# ATSAMD21G18A register map
Vendor: Microchip Technology Inc.; Series: SAMD21; File version: G
CPU: CM0+ r0p1, little endian, no MPU, no FPU, VTOR, 2 interrupt priority bits, 30 interrupts
Registers are 8-bit, read-write, reset 0x0 unless marked. A register's access mark holds for its fields unless they carry their own. Offsets are from the block's base; [hi:lo] are bit positions; {n}, {i} and the like mark numbered series; 'fields as' and 'values as' point back to an identical list.

## EVSYS — Event System Interface
Base 0x42000400; register names take the prefix EVSYS_
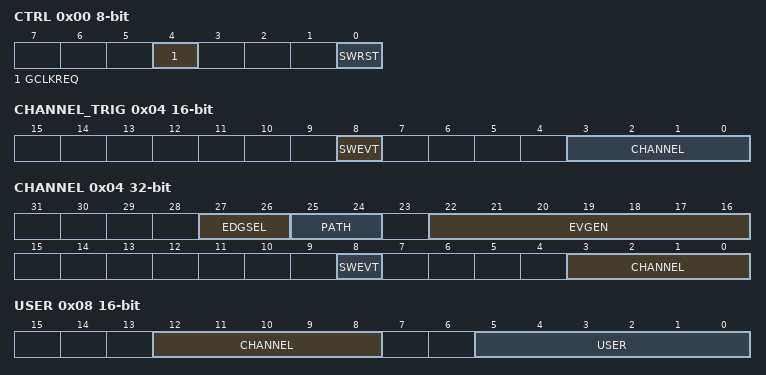
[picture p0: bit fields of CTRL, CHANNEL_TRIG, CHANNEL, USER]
0x00 CTRL wo — Control
  [4] GCLKREQ — Generic Clock Requests
  [0] SWRST — Software Reset
0x04 CHANNEL_TRIG 16-bit — Channel
  [8] SWEVT — Software Event
  [3:0] CHANNEL — Channel Selection
0x04 CHANNEL 32-bit
  [27:26] EDGSEL — Edge Detection Selection
    0=NO_EVT_OUTPUT (No event output when using the resynchronized or synchronous path); 1=RISING_EDGE (Event detection only on the rising edge of the signal from the event generator when using the resynchronized or synchronous path); 2=FALLING_EDGE (Event detection only on the falling edge of the signal from the event generator when using the resynchronized or synchronous path); 3=BOTH_EDGES (Event detection on rising and falling edges of the signal from the event generator when using the resynchronized or synchronous path)
  [25:24] PATH — Path Selection
    0=SYNCHRONOUS (Synchronous path); 1=RESYNCHRONIZED (Resynchronized path); 2=ASYNCHRONOUS (Asynchronous path)
  [22:16] EVGEN — Event Generator Selection
    0=NONE (No event generator selected); 1=RTC_CMP0 (Compare 0 (mode 0 and 1) or Alarm 0 (mode 2)); 2=RTC_CMP1 (Compare 1); 3=RTC_OVF (Overflow); {v}=RTC_PER{v-4} (Period {v-4}) (v=4..11); {v}=EIC_EXTINT{v-12} (External Interrupt {v-12}) (v=12..27); {v}=DMAC_CH{v-30} (Channel {v-30}) (v=30..33); 34=TCC0_OVF (Overflow); 35=TCC0_TRG (Trig); 36=TCC0_CNT (Counter); {v}=TCC0_MCX{v-37} (Match/Capture {v-37}) (v=37..40); 41=TCC1_OVF (Overflow); 42=TCC1_TRG (Trig); 43=TCC1_CNT (Counter); 44=TCC1_MCX0 (Match/Capture 0); 45=TCC1_MCX1 (Match/Capture 1); 46=TCC2_OVF (Overflow); 47=TCC2_TRG (Trig); 48=TCC2_CNT (Counter); 49=TCC2_MCX0 (Match/Capture 0); 50=TCC2_MCX1 (Match/Capture 1); 51=TC0_OVF (Overflow/Underflow); 52=TC0_MC0 (Match/Capture 0); 53=TC0_MC1 (Match/Capture 1); 54=TC1_OVF (Overflow/Underflow); 55=TC1_MC0 (Match/Capture 0); 56=TC1_MC1 (Match/Capture 1); 57=TC2_OVF (Overflow/Underflow); 58=TC2_MC0 (Match/Capture 0); 59=TC2_MC1 (Match/Capture 1); 60=TC3_OVF (Overflow/Underflow); 61=TC3_MC0 (Match/Capture 0); 62=TC3_MC1 (Match/Capture 1); 63=TC4_OVF (Overflow/Underflow); 64=TC4_MC0 (Match/Capture 0); 65=TC4_MC1 (Match/Capture 1); 66=ADC_RESRDY (Result Ready); 67=ADC_WINMON (Window Monitor); 68=AC_COMP0 (Comparator 0); 69=AC_COMP1 (Comparator 1); 70=AC_WIN0 (Window 0); 71=DAC_EMPTY (Data Buffer Empty); 72=PTC_EOC (End of Conversion); 73=PTC_WCOMP (Window Comparator)
  [8] SWEVT — Software Event
  [3:0] CHANNEL — Channel Selection
0x08 USER 16-bit — User Multiplexer
  [12:8] CHANNEL — Channel Event Selection
    0=No Channel Output Selected
  [5:0] USER — User Multiplexer Selection
    {v}=DMAC_CH{v} (Channel {v}) (v=0..3); 4=TCC0_EV0; 5=TCC0_EV1; {v}=TCC0_MC{v-6} (Match/Capture {v-6}) (v=6..9); 10=TCC1_EV0; 11=TCC1_EV1; 12=TCC1_MC0 (Match/Capture 0); 13=TCC1_MC1 (Match/Capture 1); 14=TCC2_EV0; 15=TCC2_EV1; 16=TCC2_MC0 (Match/Capture 0); 17=TCC2_MC1 (Match/Capture 1); {v}=TC{v-18} (v=18..22); 23=ADC_START (ADC start conversion); 24=ADC_SYNC (Flush ADC); 25=AC_COMP0 (Start comparator 0); 26=AC_COMP1 (Start comparator 1); 27=DAC_START (DAC start conversion); 28=PTC_STCONV (PTC start conversion)
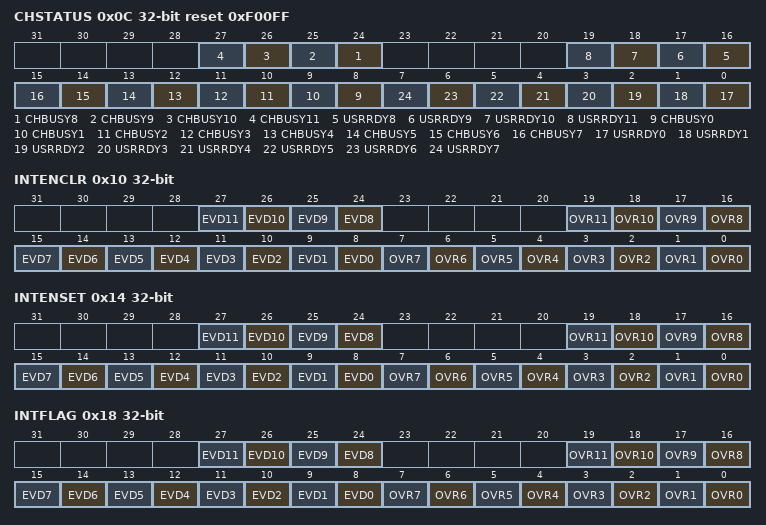
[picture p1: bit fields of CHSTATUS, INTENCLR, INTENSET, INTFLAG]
0x0C CHSTATUS 32-bit ro reset 0xF00FF — Channel Status
  [n+16] CHBUSY{n} (n=8..11) — Channel {n} Busy
  [n+8] USRRDY{n} (n=8..11) — Channel {n} User Ready
  [n+8] CHBUSY{n} (n=0..7) — Channel {n} Busy
  [n] USRRDY{n} (n=0..7) — Channel {n} User Ready
0x10 INTENCLR 32-bit — Interrupt Enable Clear
  [n+16] EVD{n} (n=8..11) — Channel {n} Event Detection Interrupt Enable
  [n+8] OVR{n} (n=8..11) — Channel {n} Overrun Interrupt Enable
  [n+8] EVD{n} (n=0..7) — Channel {n} Event Detection Interrupt Enable
  [n] OVR{n} (n=0..7) — Channel {n} Overrun Interrupt Enable
0x14 INTENSET 32-bit — Interrupt Enable Set
  fields as INTENCLR
0x18 INTFLAG 32-bit — Interrupt Flag Status and Clear
  [n+16] EVD{n} write-1-clears (n=8..11) — Channel {n} Event Detection
  [n+8] OVR{n} write-1-clears (n=8..11) — Channel {n} Overrun
  [n+8] EVD{n} write-1-clears (n=0..7) — Channel {n} Event Detection
  [n] OVR{n} write-1-clears (n=0..7) — Channel {n} Overrun
